# CY8C5588AXI_060ES1 register map
File version: 0.1
CY8C55
Registers are 8-bit, read-write, no defined reset value unless marked. A register's access mark holds for its fields unless they carry their own. Offsets are from the block's base; lines under a group give offsets from that group; [hi:lo] are bit positions; {n}, {i} and the like mark numbered series; 'fields as' and 'values as' point back to an identical list; <NAME> marks a mode.

## Memory map
0x400043AA ADCSharp size 0x17E0
0x40006402 Timer_Fin size 0x91
0x4000640A Timer_Bras size 0x91
0x4000640C Timer_Emp size 0x92
0x40006421 UART_Rpi size 0x4C — UART
0x40006424 UART_Asser size 0x145 — UART
0x40006426 UART_XBee size 0x146 — UART
0x4000642E PWM_ServoDroitBas size 0x14B
0x4000647A TimerResetCtrlBras size 0x1
0x4000647C TimerResetCtrl size 0x1
0x40006524 PWM_ServoGaucheHaut size 0x72
0x40006526 PWM_ServoDroitHaut size 0x72
0x40006528 PWM_ServoPorte size 0x72
0x4000652A PWM_ServoGaucheBas size 0x72

## PWM_ServoPorte
Base 0x40006528
0x00 PWM_ServoPorte_COMPARE_Reg 16-bit — UDB.D0 - Assigned Compare Value
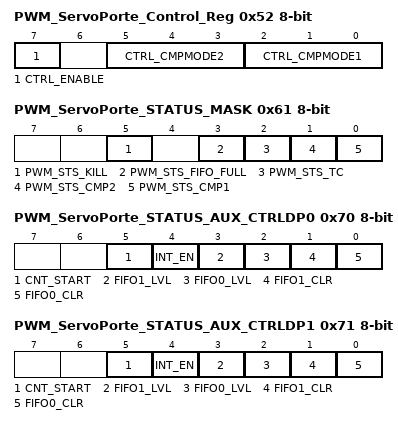
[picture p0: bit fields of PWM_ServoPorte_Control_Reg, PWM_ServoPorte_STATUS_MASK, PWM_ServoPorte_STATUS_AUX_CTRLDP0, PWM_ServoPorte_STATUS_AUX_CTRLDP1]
0x52 PWM_ServoPorte_Control_Reg — UDB Control Register - Assigned Control Register Value
  [7] CTRL_ENABLE — Enable the PWM
  [5:3] CTRL_CMPMODE2 — Compare mode 2
  [2:0] CTRL_CMPMODE1 — Compare mode 1
0x61 PWM_ServoPorte_STATUS_MASK — UDB Status bits Interrupt Mask Enable Register
  [5] PWM_STS_KILL ro — Enables the Interrupt on Kill
  [3] PWM_STS_FIFO_FULL ro — FIFO Full Status Mask
  [2] PWM_STS_TC ro — Enables the Interrupt on Terminal Count
  [1] PWM_STS_CMP2 ro — Enables the Interrupt on Compare 2
  [0] PWM_STS_CMP1 ro — Enables the Interrupt on Compare 1
0x70 PWM_ServoPorte_STATUS_AUX_CTRLDP0 — UDB Auxilliary Control Register
  [5] CNT_START — FIFO0 clear
    0=E_CNT_START0 (Disable counter); 1=E_CNT_START1 (Enable counter)
  [4] INT_EN
    0=E_INT_EN0 (Interrupt disabled); 1=E_INT_EN1 (Interrupt enabled)
  [3] FIFO1_LVL — FIFO level
    0=E_FIFO_LVL_0 (FIFO LVL: input mode: FIFO not full; output mode: FIFO not empty); 1=E_FIFO_LVL_1 (FIFO LVL: input mode: FIFO at least 1/2 empty; output mode: FIFO at least 1/2 full)
  [2] FIFO0_LVL — FIFO level
    values as FIFO1_LVL
  [1] FIFO1_CLR — FIFO1 clear
    0=E_FIFO_CLR_0 (Normal FIFO operation); 1=E_FIFO_CLR_1 (Clear FIFO state)
  [0] FIFO0_CLR — FIFO0 clear
    values as FIFO1_CLR
0x71 PWM_ServoPorte_STATUS_AUX_CTRLDP1 — UDB Auxilliary Control Register
  fields as PWM_ServoPorte_STATUS_AUX_CTRLDP0

## PWM_ServoDroitHaut
Base 0x40006526
Registers as PWM_ServoPorte (with PWM_ServoPorte read as PWM_ServoDroitHaut), without PWM_ServoPorte_Control_Reg; these are added or differ:
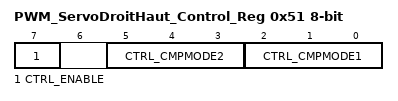
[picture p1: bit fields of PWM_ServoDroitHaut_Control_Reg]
0x51 PWM_ServoDroitHaut_Control_Reg — UDB Control Register - Assigned Control Register Value
  [7] CTRL_ENABLE — Enable the PWM
  [5:3] CTRL_CMPMODE2 — Compare mode 2
  [2:0] CTRL_CMPMODE1 — Compare mode 1

## PWM_ServoGaucheHaut
Base 0x40006524
Registers as PWM_ServoPorte (with PWM_ServoPorte read as PWM_ServoGaucheHaut), without PWM_ServoPorte_Control_Reg, PWM_ServoPorte_STATUS_MASK; these are added or differ:
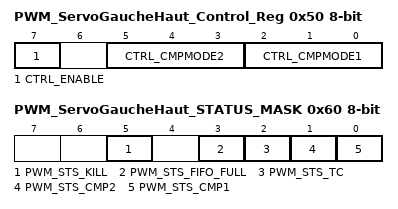
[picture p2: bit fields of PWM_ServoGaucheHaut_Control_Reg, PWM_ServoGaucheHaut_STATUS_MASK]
0x50 PWM_ServoGaucheHaut_Control_Reg — UDB Control Register - Assigned Control Register Value
  [7] CTRL_ENABLE — Enable the PWM
  [5:3] CTRL_CMPMODE2 — Compare mode 2
  [2:0] CTRL_CMPMODE1 — Compare mode 1
0x60 PWM_ServoGaucheHaut_STATUS_MASK — UDB Status bits Interrupt Mask Enable Register
  fields as PWM_ServoPorte.PWM_ServoPorte_STATUS_MASK

## PWM_ServoDroitBas
Base 0x4000642E
Registers as PWM_ServoPorte (with PWM_ServoPorte read as PWM_ServoDroitBas), without PWM_ServoPorte_Control_Reg, PWM_ServoPorte_STATUS_MASK; these are added or differ:
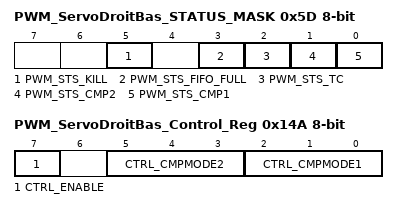
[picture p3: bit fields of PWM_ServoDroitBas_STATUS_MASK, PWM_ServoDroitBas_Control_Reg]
0x5D PWM_ServoDroitBas_STATUS_MASK — UDB Status bits Interrupt Mask Enable Register
  fields as PWM_ServoPorte.PWM_ServoPorte_STATUS_MASK
0x14A PWM_ServoDroitBas_Control_Reg — UDB Control Register - Assigned Control Register Value
  [7] CTRL_ENABLE — Enable the PWM
  [5:3] CTRL_CMPMODE2 — Compare mode 2
  [2:0] CTRL_CMPMODE1 — Compare mode 1

## PWM_ServoGaucheBas
Base 0x4000652A
Registers as PWM_ServoGaucheHaut (with PWM_ServoGaucheHaut read as PWM_ServoGaucheBas), without PWM_ServoGaucheHaut_Control_Reg; these are added or differ:
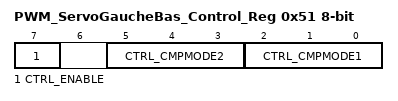
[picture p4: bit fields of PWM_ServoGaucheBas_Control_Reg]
0x51 PWM_ServoGaucheBas_Control_Reg — UDB Control Register - Assigned Control Register Value
  [7] CTRL_ENABLE — Enable the PWM
  [5:3] CTRL_CMPMODE2 — Compare mode 2
  [2:0] CTRL_CMPMODE1 — Compare mode 1
